# f2838x_cm_cm_memoryerror_regs register map
Vendor: Texas Instruments
Peripheral module from a debugger description file (folder C2000).
Address unit: 16 bits
Registers are 32-bit, read-only, no defined reset value unless marked. A register's access mark holds for its fields unless they carry their own. Offsets are as the file gives them; lines under a group give offsets from that group; [hi:lo] are bit positions; {n}, {i} and the like mark numbered series; 'fields as' and 'values as' point back to an identical list; <NAME> marks a mode.

## CM_MEMORYERROR_REGS — CM MEMORYERROR Registers
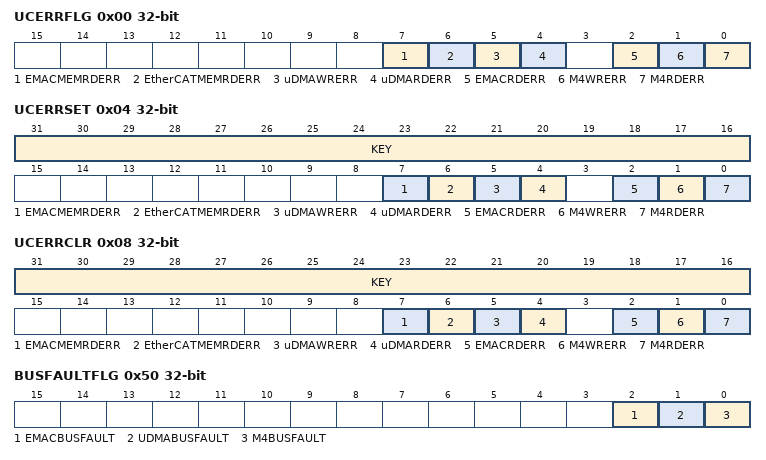
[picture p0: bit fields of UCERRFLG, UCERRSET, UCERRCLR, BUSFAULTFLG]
0x00 UCERRFLG — Uncorrectable Error Flag Register
  [7] EMACMEMRDERR — EMAC IP RAM Uncorrectable Read Error Flag
  [6] EtherCATMEMRDERR — EtherCAT IP RAM Uncorrectable Read Error Flag
  [5] uDMAWRERR — uDMA Uncorrectable Write Error Flag
  [4] uDMARDERR — uDMA Uncorrectable Read Error Flag
  [2] EMACRDERR — EMAC Uncorrectable Read Error Flag
  [1] M4WRERR — M4 Uncorrectable Write Error Flag
  [0] M4RDERR — M4 Uncorrectable Read Error Flag
0x04 UCERRSET rw — Uncorrectable Error Flag Set Register
  [31:16] KEY — KEY to allow write access
  [7] EMACMEMRDERR — EMAC IP RAM Uncorrectable Read Error Flag set
  [6] EtherCATMEMRDERR — EtherCAT IP RAM Uncorrectable Read Error Flag set
  [5] uDMAWRERR — uDMA Uncorrectable Write Error Flag Set
  [4] uDMARDERR — uDMA Uncorrectable Read Error Flag Set
  [2] EMACRDERR — EMAC Uncorrectable Read Error Flag Set
  [1] M4WRERR — M4 Uncorrectable Write Error Flag Set
  [0] M4RDERR — M4 Uncorrectable Read Error Flag Set
0x08 UCERRCLR rw — Uncorrectable Error Flag Clear Register
  [31:16] KEY — KEY to allow write access
  [7] EMACMEMRDERR — EMAC IP RAM Uncorrectable Read Error Flag Clear
  [6] EtherCATMEMRDERR — EtherCAT IP RAM Uncorrectable Read Error Flag Clear
  [5] uDMAWRERR — uDMA Uncorrectable Write Error Flag Clear
  [4] uDMARDERR — uDMA Uncorrectable Read Error Flag Clear
  [2] EMACRDERR — EMAC Uncorrectable Read Error Flag Clear
  [1] M4WRERR — M4 Uncorrectable Write Error Flag Clear
  [0] M4RDERR — M4 Uncorrectable Read Error Flag Clear
0x0C UCM4EADDR — Uncorrectable M4 Error Address
  [31:0] UCM4EADDR — Uncorrectable M4 error address register.
0x10 UCEMACEADDR — Uncorrectable EMAC Error Address
  [31:0] UCEMACEADDR — Uncorrectable EMAC error address register.
0x14 UCuDMAEADDR — Uncorrectable uDMA Error Address
  [31:0] UCuDMAEADDR — Uncorrectable uDMA error address register.
0x18 UCEtherCATMEMREADDR — Uncorrectable EtherCAT IP RAM Read Error Address
  [31:0] UCEtherCATMEMREADDR — Uncorrectable EtherCAT IP RAM read error address register.
0x1C UCEMACMEMREADDR — Uncorrectable EMAC IP RAM Read Error Address
  [31:0] UCEMACMEMREADDR — Uncorrectable EMAC IP RAM read error address register.
0x50 BUSFAULTFLG — BusFault Flag register
  [2] EMACBUSFAULT — EMAC busfault Flag
  [1] UDMABUSFAULT — UDMA busfault Flag
  [0] M4BUSFAULT — M4 busfault Flag
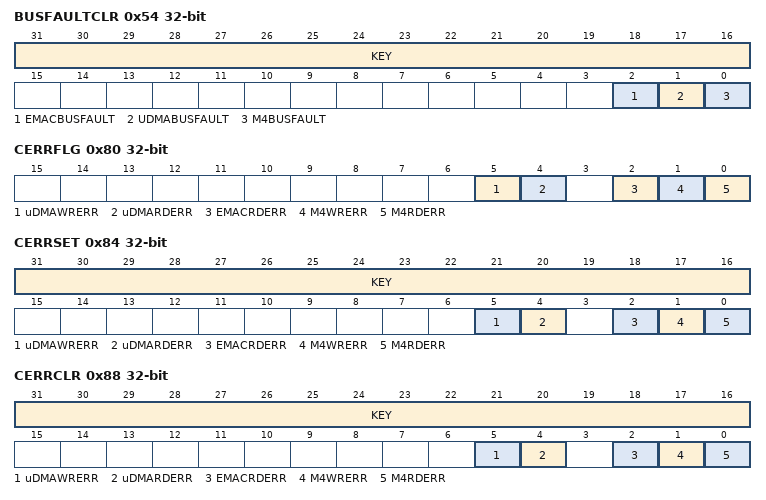
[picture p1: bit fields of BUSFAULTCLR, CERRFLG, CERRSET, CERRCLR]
0x54 BUSFAULTCLR rw — BusFault Flag clear register
  [31:16] KEY — KEY to allow write access
  [2] EMACBUSFAULT — EMAC busfault Flag Clear
  [1] UDMABUSFAULT — UDMA busfault Flag Clear
  [0] M4BUSFAULT — M4 busfault Flag Clear
0x58 M4BUSFAULTADDR — M4 busfault address
  [31:0] M4BUSFAULTADDRESS
0x5C uDMABUSFAULTADDR — uDMA busfault address
  [31:0] UDMABUSFAULTADDRESS
0x60 EMACBUSFAULTADDR — EMAC busfault address
  [31:0] EMACBUSFAULTADDRESS
0x80 CERRFLG — Correctable Error Flag Register
  [5] uDMAWRERR — uDMA Correctable Write Error Flag
  [4] uDMARDERR — uDMA Correctable Read Error Flag
  [2] EMACRDERR — EMAC Correctable Read Error Flag
  [1] M4WRERR — M4 Correctable Write Error Flag
  [0] M4RDERR — M4 Correctable Read Error Flag
0x84 CERRSET rw — Correctable Error Flag Set Register
  [31:16] KEY — KEY to allow write access
  [5] uDMAWRERR — uDMA Correctable Write Error Flag Set
  [4] uDMARDERR — uDMA Correctable Read Error Flag Set
  [2] EMACRDERR — EMAC Correctable Read Error Flag Set
  [1] M4WRERR — M4 Correctable Write Error Flag Set
  [0] M4RDERR — M4 Correctable Read Error Flag Set
0x88 CERRCLR rw — Correctable Error Flag Clear Register
  [31:16] KEY — KEY to allow write access
  [5] uDMAWRERR — uDMA Correctable Write Error Flag Clear
  [4] uDMARDERR — uDMA Correctable Read Error Flag Clear
  [2] EMACRDERR — EMAC Correctable Read Error Flag Clear
  [1] M4WRERR — M4 Correctable Write Error Flag Clear
  [0] M4RDERR — M4 Correctable Read Error Flag Clear
0x8C CM4EADDR — Correctable M4 Error Address
  [31:0] CM4EADDR — Correctable M4 error address register.
0x90 CEMACEADDR — Correctable EMAC Error Address
  [31:0] CEMACEADDR — Correctable EMAC error address register.
0x94 CuDMAEADDR — Correctable uDMA Error Address
  [31:0] CuDMAEADDR — Correctable uDMA error address register.
0xC0 CERRCNT rw — Correctable Error Count Register
  [31:0] CERRCNT — Correctable error count.
0xC4 CERRTHRES rw — Correctable Error Threshold Value Register
  [31:0] CERRTHRES — Correctable error threshold.
0xC8 CEINTFLG — Correctable Error Interrupt Flag Status Register
  [0] CEINTFLAG — Total corrected error count exceeded threshold flag.
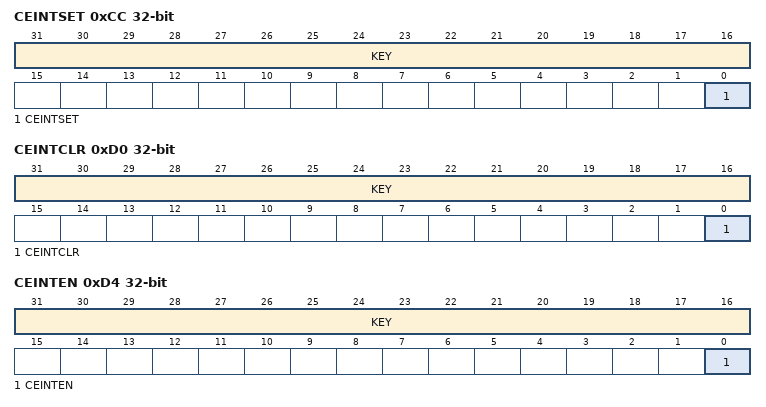
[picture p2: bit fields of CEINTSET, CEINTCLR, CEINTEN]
0xCC CEINTSET rw — Correctable Error Interrupt Flag Set Register
  [31:16] KEY — KEY to allow write access
  [0] CEINTSET — Total corrected error count exceeded flag set.
0xD0 CEINTCLR rw — Correctable Error Interrupt Flag Clear Register
  [31:16] KEY — KEY to allow write access
  [0] CEINTCLR — M4 Corrected Error Threshold Exceeded Error Clear.
0xD4 CEINTEN rw — Correctable Error Interrupt Enable Register
  [31:16] KEY — KEY to allow write access
  [0] CEINTEN — M4 Correctable Error Interrupt Enable.
